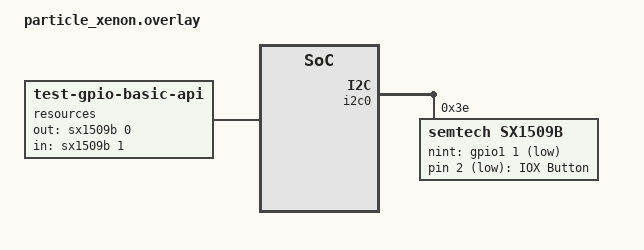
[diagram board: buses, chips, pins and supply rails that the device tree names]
/*
 * Copyright (c) 2019 Nordic Semiconductor ASA
 *
 * SPDX-License-Identifier: Apache-2.0
 */

/ {
	resources {
		compatible = "test-gpio-basic-api";
		out-gpios = <&sx1509b 0 0>; /* EXT0 */
		in-gpios = <&sx1509b 1 0>;  /* EXT1 */
	};

	gpio_keys {
		compatible = "gpio-keys";
		iox_button: button_2 {
			gpios = <&sx1509b 2 (GPIO_PULL_UP | GPIO_ACTIVE_LOW)>;
			label = "IOX Button";
		};
	};
};

&i2c0 {
	sx1509b: sx1509b@3e {
		compatible = "semtech,sx1509b";
		reg = <0x3e>;
		gpio-controller;
		#gpio-cells = <2>;
		ngpios = <16>;
		nint-gpios = <&gpio1 1 (GPIO_PULL_UP | GPIO_ACTIVE_LOW)>;
	};
};
